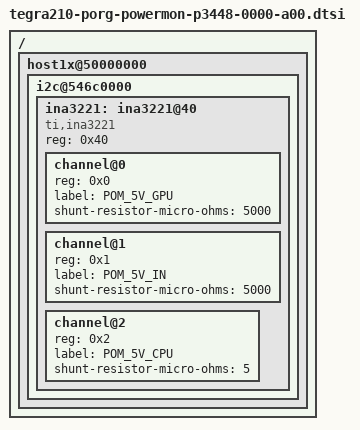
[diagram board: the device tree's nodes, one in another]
/*
 * Copyright (c) 2018, NVIDIA CORPORATION.  All rights reserved.
 *
 * This program is free software; you can redistribute it and/or modify
 * it under the terms of the GNU General Public License as published by
 * the Free Software Foundation; either version 2 of the License, or
 * (at your option) any later version.
 *
 * This program is distributed in the hope that it will be useful, but WITHOUT
 * ANY WARRANTY; without even the implied warranty of MERCHANTABILITY or
 * FITNESS FOR A PARTICULAR PURPOSE.  See the GNU General Public License for
 * more details.
 *
 * You should have received a copy of the GNU General Public License along
 * with this program; if not, write to the Free Software Foundation, Inc.,
 * 51 Franklin Street, Fifth Floor, Boston, MA  02110-1301, USA.
 */
/ {
	host1x@50000000 {
		i2c@546c0000 {
			ina3221: ina3221@40 {
				compatible = "ti,ina3221";
				reg = <0x40>;
				status="okay";
				#io-channel-cells = <1>;
				#address-cells = <1>;
				#size-cells = <0>;
				channel@0 {
					reg = <0x0>;
					label = "POM_5V_GPU";
					shunt-resistor-micro-ohms = <5000>;
				};

				channel@1 {
					reg = <0x1>;
					label = "POM_5V_IN";
					shunt-resistor-micro-ohms = <5000>;
				};

				channel@2 {
					reg = <0x2>;
					label = "POM_5V_CPU";
					shunt-resistor-micro-ohms = <5>;
				};
			};
		};
	};
};
